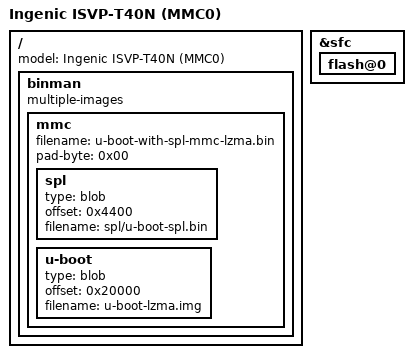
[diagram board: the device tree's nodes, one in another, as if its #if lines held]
// SPDX-License-Identifier: GPL-2.0+
/*
 * Binman image description for the Ingenic ISVP-T40 SFC-NOR boot.
 *
 * Mirrors the A1 binman layout - T40 is the XBurst2 sibling of A1 and
 * uses the same vendor `0x03040506 / 0x55aa5502 / 0x000000aa` SFC-NOR
 * boot header at flash offset 0, with LZMA U-Boot at 0x10000 (the SPL
 * grew past the prior 0x8000 ceiling once DM-in-SPL + UCLASS_RAM
 * landed; 0x10000 = 64 KiB SPL window matches T41 and stays inside
 * the vendor BIG_SPL 100 KiB load limit). The bootrom's FUN_bfc02070
 * Port-A SFC path scans for the 0x55aa5502 marker in the first sector.
 *
 * The SPL header is a plain CRC + SPL_LENGTH header (no INGE block).
 * Earlier T40 builds carried an `ingenic,inge-descriptors` table here
 * to make the bootrom program APLL/MPLL/CPCCR/SFC before SPL entry -
 * needed only while the SPL printed pre-PLL debug banners against a
 * hard-coded baud divisor. With DM-in-SPL the SPL programs its own
 * clocks in board_init_f before any UART output, so the INGE pre-
 * programming is redundant: HW-verified 2026-05-28 that T40NN cold-
 * boots identically with and without it. The etype still supports the
 * property (tools/binman/etype/ingenic_t31_spl.py) for a vendor-style
 * SPL that needs clocks set before its own init.
 *
 * 'make' produces:
 *   u-boot-spl-t40.bin       : SPL with the finalized SFC-NOR boot
 *                              header, bootable standalone.
 *   u-boot-with-spl-lzma.bin : headered SPL at offset 0 + LZMA U-Boot
 *                              at 0x10000 - flash at offset 0.
 */

#include "t40-isvp-uboot-common.dtsi"

/ {
	binman: binman {
		multiple-images;
	};
};

&binman {
#if defined(CONFIG_SPL_MMC)
	/*
	 * MSC/SD-card boot image (isvp_t40n_msc0). Plain SPL blob with the
	 * mask-ROM "MSPL" magic from start.S; the ROM defaults the SD load
	 * to 0x19000, which covers BSS. SPL at SD sector 34 (0x4400); U-Boot
	 * from SYS_MMCSD_RAW_MODE_U_BOOT_SECTOR (0x100 = byte 0x20000).
	 */
	mmc {
		filename = "u-boot-with-spl-mmc-lzma.bin";
		pad-byte = <0x00>;

		spl {
			type = "blob";
			offset = <0x4400>;
			filename = "spl/u-boot-spl.bin";
		};

		u-boot {
			type = "blob";
			offset = <0x20000>;
			filename = "u-boot-lzma.img";
		};
	};
#else
	u-boot-spl-t40 {
		filename = "u-boot-spl-t40.bin";

		ingenic-t31-spl {
			filename = "spl/u-boot-spl.bin";

			/*
			 * Cold-boot SRAM coverage. The bootrom locks cache lines
			 * as SRAM only for MIN(SPL_LENGTH, _DAT_80000000) bytes
			 * starting at CONFIG_SPL_TEXT_BASE. With DM-in-SPL the
			 * SPL file (~60 KB) ends WELL before our SPL_BSS_START_ADDR
			 * (0x80014000), so BSS accesses miss the cache-locked
			 * region and fault on uninitialised DRAM. Tell the etype
			 * to stamp SPL_LENGTH up to BSS_MAX (= 0x16000 from
			 * SPL_TEXT_BASE, covering BSS_START_ADDR 0x80014000 +
			 * BSS_MAX_SIZE 0x2000); the bootrom overloads past file-
			 * EOF into the U-Boot proper region (junk bytes land in
			 * BSS area which gets zeroed at SPL startup anyway).
			 * Empirical: cold-boot SFC NOR is silent without this
			 * stamp, clean to => prompt with it (verified on T40NN
			 * 2026-05-28).
			 */
			ingenic,min-spl-length = <0x16000>;
		};
	};

	flash {
		filename = "u-boot-with-spl-lzma.bin";
		pad-byte = <0xff>;

		spl {
			type = "blob";
			offset = <0x0>;
			filename = "u-boot-spl-t40.bin";
		};

		u-boot {
			type = "blob";
			offset = <0x14000>;
			filename = "u-boot-lzma.img";
		};
	};
#endif
};

#if defined(CONFIG_SPL_MMC)
/ {
	model = "Ingenic ISVP-T40N (MMC0)";
};
#endif

/*
 * The SFC-NOR flash@0 is an SPL node on the NOR boards, so tag it here
 * (not in t40-isvp-uboot-common.dtsi - the NAND t40xp flash@0 is not an
 * SPL node). Relocated from t40-isvp-nor.dtsi.
 */
&sfc {
	flash@0 { bootph-all; };
};
